# DDR16SS0_CTLPHY_WRAP_CTL_CFG_CTLCFG register map
Vendor: Texas Instruments
Registers are 32-bit, read-write, reset 0x0 unless marked. A register's access mark holds for its fields unless they carry their own. Offsets are as the file gives them; [hi:lo] are bit positions; {n}, {i} and the like mark numbered series.

## DDR16SS0_CTLPHY_WRAP_CTL_CFG_CTLCFG (part 6 of 9)
0x23DC CTLPHY_WRAP__CTL_CFG__CTLCFG_DENALI_PI_247
  [20:0] PI_TDFI_CTRLUPD_MAX_F0 — Defines the DFI tCTRLUPD_MAX timing parameter [in DFI clocks] for frequency set 0, the maximum cycles that dfi_ctrlupd_req can be asserted. If programmed to a non-zero, a timing violation will cause an interrupt and bit [1] set in the PI_UPDATE_ERROR_STATUS parameter.
0x23E0 CTLPHY_WRAP__CTL_CFG__CTLCFG_DENALI_PI_248
  [31:0] PI_TDFI_CTRLUPD_INTERVAL_F0 — Defines the DFI tCTRLUPD_INTERVAL timing parameter [in DFI clocks] for frequency set 0, the maximum cycles between dfi_ctrlupd_req assertions. If programmed to a non-zero, a timing violation will cause an interrupt and bit [0] set in the PI_UPDATE_ERROR_STATUS parameter.
0x23E4 CTLPHY_WRAP__CTL_CFG__CTLCFG_DENALI_PI_249
  [20:0] PI_TDFI_CTRLUPD_MAX_F1 — Defines the DFI tCTRLUPD_MAX timing parameter [in DFI clocks] for frequency set 1, the maximum cycles that dfi_ctrlupd_req can be asserted. If programmed to a non-zero, a timing violation will cause an interrupt and bit [1] set in the PI_UPDATE_ERROR_STATUS parameter.
0x23E8 CTLPHY_WRAP__CTL_CFG__CTLCFG_DENALI_PI_250
  [31:0] PI_TDFI_CTRLUPD_INTERVAL_F1 — Defines the DFI tCTRLUPD_INTERVAL timing parameter [in DFI clocks] for frequency set 1, the maximum cycles between dfi_ctrlupd_req assertions. If programmed to a non-zero, a timing violation will cause an interrupt and bit [0] set in the PI_UPDATE_ERROR_STATUS parameter.
0x23EC CTLPHY_WRAP__CTL_CFG__CTLCFG_DENALI_PI_251
  [20:0] PI_TDFI_CTRLUPD_MAX_F2 — Defines the DFI tCTRLUPD_MAX timing parameter [in DFI clocks] for frequency set 2, the maximum cycles that dfi_ctrlupd_req can be asserted. If programmed to a non-zero, a timing violation will cause an interrupt and bit [1] set in the PI_UPDATE_ERROR_STATUS parameter.
0x23F0 CTLPHY_WRAP__CTL_CFG__CTLCFG_DENALI_PI_252
  [31:0] PI_TDFI_CTRLUPD_INTERVAL_F2 — Defines the DFI tCTRLUPD_INTERVAL timing parameter [in DFI clocks] for frequency set 2, the maximum cycles between dfi_ctrlupd_req assertions. If programmed to a non-zero, a timing violation will cause an interrupt and bit [0] set in the PI_UPDATE_ERROR_STATUS parameter.
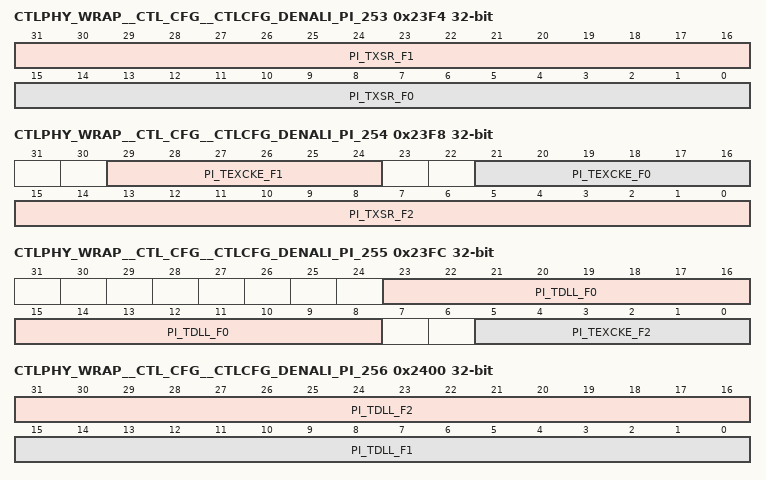
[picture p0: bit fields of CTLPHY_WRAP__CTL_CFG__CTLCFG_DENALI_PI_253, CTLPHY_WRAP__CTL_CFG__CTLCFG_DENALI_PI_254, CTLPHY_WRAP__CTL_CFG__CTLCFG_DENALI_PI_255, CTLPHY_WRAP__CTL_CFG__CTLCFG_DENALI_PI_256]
0x23F4 CTLPHY_WRAP__CTL_CFG__CTLCFG_DENALI_PI_253
  [31:16] PI_TXSR_F1 — DRAM TXSR value for frequency set 1 in cycles.
  [15:0] PI_TXSR_F0 — DRAM TXSR value for frequency set 0 in cycles.
0x23F8 CTLPHY_WRAP__CTL_CFG__CTLCFG_DENALI_PI_254
  [29:24] PI_TEXCKE_F1 — DRAM CKE low after SREF command timing for frequency set 1.
  [21:16] PI_TEXCKE_F0 — DRAM CKE low after SREF command timing for frequency set 0.
  [15:0] PI_TXSR_F2 — DRAM TXSR value for frequency set 2 in cycles.
0x23FC CTLPHY_WRAP__CTL_CFG__CTLCFG_DENALI_PI_255
  [23:8] PI_TDLL_F0 — DRAM tDLL value for frequency set 0 in cycles.
  [5:0] PI_TEXCKE_F2 — DRAM CKE low after SREF command timing for frequency set 2.
0x2400 CTLPHY_WRAP__CTL_CFG__CTLCFG_DENALI_PI_256
  [31:16] PI_TDLL_F2 — DRAM tDLL value for frequency set 2 in cycles.
  [15:0] PI_TDLL_F1 — DRAM tDLL value for frequency set 1 in cycles.
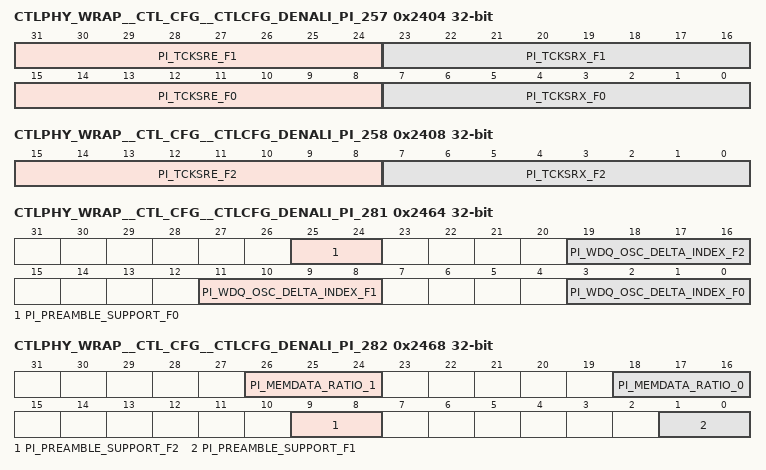
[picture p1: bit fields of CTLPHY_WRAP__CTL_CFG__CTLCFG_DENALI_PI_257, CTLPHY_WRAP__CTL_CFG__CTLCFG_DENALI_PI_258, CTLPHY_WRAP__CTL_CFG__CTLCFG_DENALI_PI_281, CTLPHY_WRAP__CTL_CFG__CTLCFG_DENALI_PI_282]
0x2404 CTLPHY_WRAP__CTL_CFG__CTLCFG_DENALI_PI_257
  [31:24] PI_TCKSRE_F1 — DRAM tCKSRE value.
  [23:16] PI_TCKSRX_F1 — DRAM tCKSRX value.
  [15:8] PI_TCKSRE_F0 — DRAM tCKSRE value.
  [7:0] PI_TCKSRX_F0 — DRAM tCKSRX value.
0x2408 CTLPHY_WRAP__CTL_CFG__CTLCFG_DENALI_PI_258
  [15:8] PI_TCKSRE_F2 — DRAM tCKSRE value.
  [7:0] PI_TCKSRX_F2 — DRAM tCKSRX value.
0x240C CTLPHY_WRAP__CTL_CFG__CTLCFG_DENALI_PI_259
  [23:0] PI_TINIT_F0 — DRAM tINIT value for frequency set 0 in cycles.
{0x2000+4i} CTLPHY_WRAP__CTL_CFG__CTLCFG_DENALI_PI_{i} (i=260..262)
  [23:0] PI_TINIT{i-257}_F0 — DRAM tINIT{i-257} value for frequency set 0 in cycles.
0x241C CTLPHY_WRAP__CTL_CFG__CTLCFG_DENALI_PI_263
  [15:0] PI_TXSNR_F0 — DRAM tXSNR value for frequency set 0 in cycles.
0x2420 CTLPHY_WRAP__CTL_CFG__CTLCFG_DENALI_PI_264
  [23:0] PI_TINIT_F1 — DRAM tINIT value for frequency set 1 in cycles.
{0x2000+4i} CTLPHY_WRAP__CTL_CFG__CTLCFG_DENALI_PI_{i} (i=265..267)
  [23:0] PI_TINIT{i-262}_F1 — DRAM tINIT{i-262} value for frequency set 1 in cycles.
0x2430 CTLPHY_WRAP__CTL_CFG__CTLCFG_DENALI_PI_268
  [15:0] PI_TXSNR_F1 — DRAM tXSNR value for frequency set 1 in cycles.
0x2434 CTLPHY_WRAP__CTL_CFG__CTLCFG_DENALI_PI_269
  [23:0] PI_TINIT_F2 — DRAM tINIT value for frequency set 2 in cycles.
{0x2000+4i} CTLPHY_WRAP__CTL_CFG__CTLCFG_DENALI_PI_{i} (i=270..272)
  [23:0] PI_TINIT{i-267}_F2 — DRAM tINIT{i-267} value for frequency set 2 in cycles.
0x2444 CTLPHY_WRAP__CTL_CFG__CTLCFG_DENALI_PI_273
  [15:0] PI_TXSNR_F2 — DRAM tXSNR value for frequency set 2 in cycles.
0x2448 CTLPHY_WRAP__CTL_CFG__CTLCFG_DENALI_PI_274
  [27:16] PI_TZQCAL_F0 — Holds the DRAM ZQCAL value for frequency set 0 in cycles.
0x244C CTLPHY_WRAP__CTL_CFG__CTLCFG_DENALI_PI_275
  [6:0] PI_TZQLAT_F0 — Holds the DRAM ZQLAT value for frequency set 0 in cycles.
0x2450 CTLPHY_WRAP__CTL_CFG__CTLCFG_DENALI_PI_276
  [27:16] PI_TZQCAL_F1 — Holds the DRAM ZQCAL value for frequency set 1 in cycles.
0x2454 CTLPHY_WRAP__CTL_CFG__CTLCFG_DENALI_PI_277
  [6:0] PI_TZQLAT_F1 — Holds the DRAM ZQLAT value for frequency set 1 in cycles.
0x2458 CTLPHY_WRAP__CTL_CFG__CTLCFG_DENALI_PI_278
  [27:16] PI_TZQCAL_F2 — Holds the DRAM ZQCAL value for frequency set 2 in cycles.
0x245C CTLPHY_WRAP__CTL_CFG__CTLCFG_DENALI_PI_279
  [6:0] PI_TZQLAT_F2 — Holds the DRAM ZQLAT value for frequency set 2 in cycles.
0x2460 CTLPHY_WRAP__CTL_CFG__CTLCFG_DENALI_PI_280 access not given reset not defined
0x2464 CTLPHY_WRAP__CTL_CFG__CTLCFG_DENALI_PI_281
  [25:24] PI_PREAMBLE_SUPPORT_F0 — bit0: Selection of one or two cycle preamble for read burst transfers. bit1: Selection of one or two cycles write burst transfers for NON-DDR5,one or multi[up to four] cycles write burst transfers for DDR5.
  [19:16] PI_WDQ_OSC_DELTA_INDEX_F2 — WDQ DQS delay delta index for OSC triggered periodic training for frequency set 2. If the value is n, the delay is 2^n/512 cycle.
  [11:8] PI_WDQ_OSC_DELTA_INDEX_F1 — WDQ DQS delay delta index for OSC triggered periodic training for frequency set 1. If the value is n, the delay is 2^n/512 cycle.
  [3:0] PI_WDQ_OSC_DELTA_INDEX_F0 — WDQ DQS delay delta index for OSC triggered periodic training for frequency set 0. If the value is n, the delay is 2^n/512 cycle.
0x2468 CTLPHY_WRAP__CTL_CFG__CTLCFG_DENALI_PI_282
  [26:24] PI_MEMDATA_RATIO_1 — Defines the ratio of the DRAM device size on chip select 1 to the memory data width. Program with the log2 ratio of the memory data width to the device data width.
  [18:16] PI_MEMDATA_RATIO_0 — Defines the ratio of the DRAM device size on chip select 0 to the memory data width. Program with the log2 ratio of the memory data width to the device data width.
  [9:8] PI_PREAMBLE_SUPPORT_F2 — bit0: Selection of one or two cycle preamble for read burst transfers. bit1: Selection of one or two cycles write burst transfers for NON-DDR5,one or multi[up to four] cycles write burst transfers for DDR5.
  [1:0] PI_PREAMBLE_SUPPORT_F1 — bit0: Selection of one or two cycle preamble for read burst transfers. bit1: Selection of one or two cycles write burst transfers for NON-DDR5,one or multi[up to four] cycles write burst transfers for DDR5.
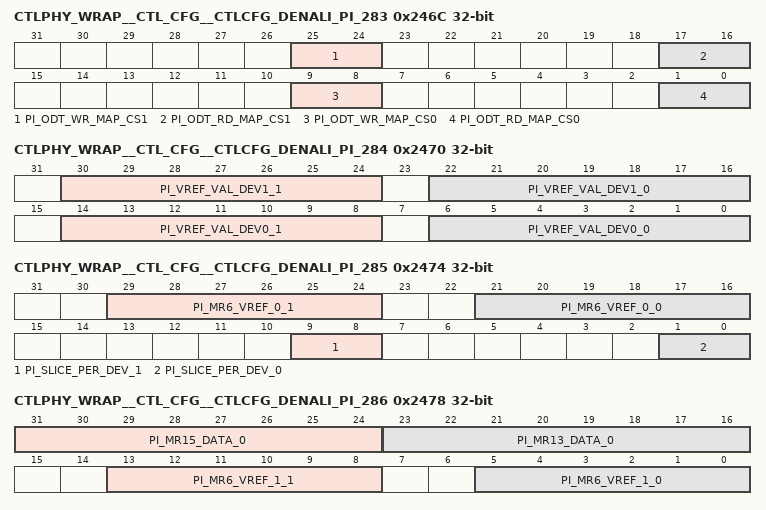
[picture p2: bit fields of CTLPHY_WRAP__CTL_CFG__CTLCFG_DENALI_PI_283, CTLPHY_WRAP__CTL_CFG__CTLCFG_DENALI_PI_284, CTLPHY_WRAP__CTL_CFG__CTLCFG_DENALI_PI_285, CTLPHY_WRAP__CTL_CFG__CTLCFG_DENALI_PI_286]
0x246C CTLPHY_WRAP__CTL_CFG__CTLCFG_DENALI_PI_283
  [25:24] PI_ODT_WR_MAP_CS1 — Determines which chip[s] will have termination when a write occurs on chip select 1. Set bit X to enable termination on csX when cs1 is performing a write.
  [17:16] PI_ODT_RD_MAP_CS1 — Determines which chip[s] will have termination when a read occurs on chip select 1. Set bit X to enable termination on csX when cs1 is performing a read.
  [9:8] PI_ODT_WR_MAP_CS0 — Determines which chip[s] will have termination when a write occurs on chip select 0. Set bit X to enable termination on csX when cs0 is performing a write.
  [1:0] PI_ODT_RD_MAP_CS0 — Determines which chip[s] will have termination when a read occurs on chip select 0. Set bit X to enable termination on csX when cs0 is performing a read.
0x2470 CTLPHY_WRAP__CTL_CFG__CTLCFG_DENALI_PI_284
  [30:24] PI_VREF_VAL_DEV1_1 — Defines the range and value for VREF training for DRAM 1 for CS 1. If the PI_VREF_PDA_EN parameter is not set, device 0 values are used for all devices.
  [22:16] PI_VREF_VAL_DEV1_0 — Defines the range and value for VREF training for DRAM 1 for CS 0. If the PI_VREF_PDA_EN parameter is not set, device 0 values are used for all devices.
  [14:8] PI_VREF_VAL_DEV0_1 — Defines the range and value for VREF training for DRAM 0 for CS 1. If the PI_VREF_PDA_EN parameter is not set, device 0 values are used for all devices.
  [6:0] PI_VREF_VAL_DEV0_0 — Defines the range and value for VREF training for DRAM 0 for CS 0. If the PI_VREF_PDA_EN parameter is not set, device 0 values are used for all devices.
0x2474 CTLPHY_WRAP__CTL_CFG__CTLCFG_DENALI_PI_285 access per field
  [29:24] PI_MR6_VREF_0_1 ro — The parameter stores the vref value of every devices of the same CS. It is updated after WDQLVL PDA mode completed. READ-ONLY.
  [21:16] PI_MR6_VREF_0_0 ro — The parameter stores the vref value of every devices of the same CS. It is updated after WDQLVL PDA mode completed. READ-ONLY.
  [9:8] PI_SLICE_PER_DEV_1 rw — Indicates the number of data slices per memory device. The device width divided by 8.
  [1:0] PI_SLICE_PER_DEV_0 rw — Indicates the number of data slices per memory device. The device width divided by 8.
0x2478 CTLPHY_WRAP__CTL_CFG__CTLCFG_DENALI_PI_286 access per field
  [31:24] PI_MR15_DATA_0 rw — Data to program into memory mode register 15 for chip select 0.
  [23:16] PI_MR13_DATA_0 rw — Data to program into memory mode register 13 for chip select 0.
  [13:8] PI_MR6_VREF_1_1 ro — The parameter stores the vref value of every devices of the same CS. It is updated after WDQLVL PDA mode completed. READ-ONLY.
  [5:0] PI_MR6_VREF_1_0 ro — The parameter stores the vref value of every devices of the same CS. It is updated after WDQLVL PDA mode completed. READ-ONLY.
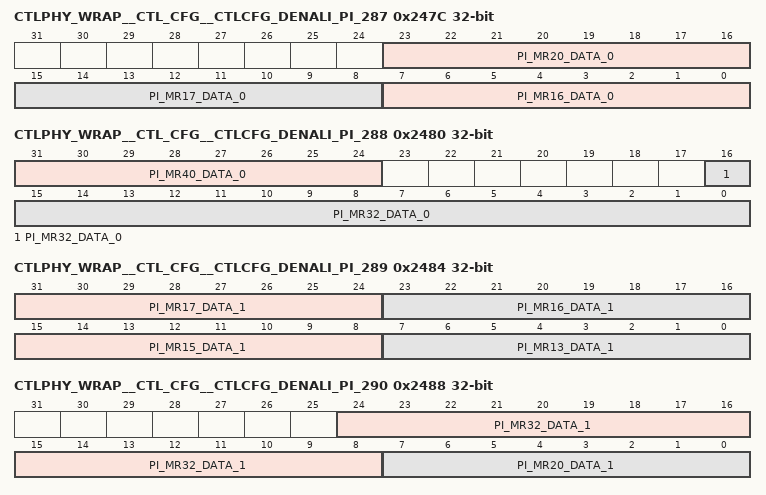
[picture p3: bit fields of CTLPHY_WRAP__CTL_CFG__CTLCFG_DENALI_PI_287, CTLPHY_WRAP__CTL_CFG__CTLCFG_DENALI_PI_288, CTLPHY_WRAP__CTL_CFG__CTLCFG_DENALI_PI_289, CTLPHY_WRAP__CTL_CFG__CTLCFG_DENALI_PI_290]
0x247C CTLPHY_WRAP__CTL_CFG__CTLCFG_DENALI_PI_287
  [23:16] PI_MR20_DATA_0 — Data to program into memory mode register 20 for chip select 0.
  [15:8] PI_MR17_DATA_0 — Data to program into memory mode register 17 for chip select 0.
  [7:0] PI_MR16_DATA_0 — Data to program into memory mode register 16 for chip select 0.
0x2480 CTLPHY_WRAP__CTL_CFG__CTLCFG_DENALI_PI_288
  [31:24] PI_MR40_DATA_0 — Data to program into memory mode register 40 for chip select 0.
  [16:0] PI_MR32_DATA_0 — Data to program into memory mode register 32 for chip select 0.
0x2484 CTLPHY_WRAP__CTL_CFG__CTLCFG_DENALI_PI_289
  [31:24] PI_MR17_DATA_1 — Data to program into memory mode register 17 for chip select 1.
  [23:16] PI_MR16_DATA_1 — Data to program into memory mode register 16 for chip select 1.
  [15:8] PI_MR15_DATA_1 — Data to program into memory mode register 15 for chip select 1.
  [7:0] PI_MR13_DATA_1 — Data to program into memory mode register 13 for chip select 1.
0x2488 CTLPHY_WRAP__CTL_CFG__CTLCFG_DENALI_PI_290
  [24:8] PI_MR32_DATA_1 — Data to program into memory mode register 32 for chip select 1.
  [7:0] PI_MR20_DATA_1 — Data to program into memory mode register 20 for chip select 1.
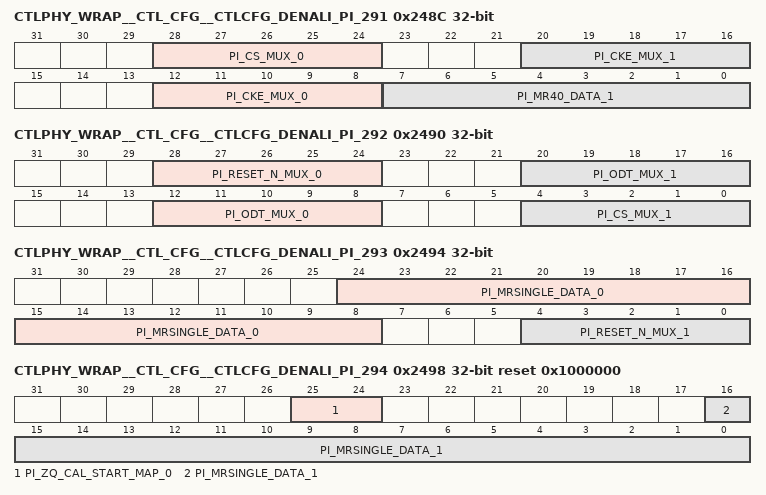
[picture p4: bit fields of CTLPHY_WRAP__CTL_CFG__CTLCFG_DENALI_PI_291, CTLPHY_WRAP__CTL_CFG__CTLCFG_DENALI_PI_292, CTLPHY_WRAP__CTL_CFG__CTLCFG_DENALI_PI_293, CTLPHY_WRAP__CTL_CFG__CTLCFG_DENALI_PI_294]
0x248C CTLPHY_WRAP__CTL_CFG__CTLCFG_DENALI_PI_291
  [28:24] PI_CS_MUX_0 — Command pin CS_0 mux selector
  [20:16] PI_CKE_MUX_1 — Command pin CKE_1 mux selector
  [12:8] PI_CKE_MUX_0 — Command pin CKE_0 mux selector
  [7:0] PI_MR40_DATA_1 — Data to program into memory mode register 40 for chip select 1.
0x2490 CTLPHY_WRAP__CTL_CFG__CTLCFG_DENALI_PI_292
  [28:24] PI_RESET_N_MUX_0 — Command pin RESET_N_0 mux selector
  [20:16] PI_ODT_MUX_1 — Command pin ODT_1 mux selector
  [12:8] PI_ODT_MUX_0 — Command pin ODT_0 mux selector
  [4:0] PI_CS_MUX_1 — Command pin CS_1 mux selector
0x2494 CTLPHY_WRAP__CTL_CFG__CTLCFG_DENALI_PI_293
  [24:8] PI_MRSINGLE_DATA_0 — Data to program into memory mode register single write to chip select 0.
  [4:0] PI_RESET_N_MUX_1 — Command pin RESET_N_1 mux selector
0x2498 CTLPHY_WRAP__CTL_CFG__CTLCFG_DENALI_PI_294 reset 0x1000000
  [25:24] PI_ZQ_CAL_START_MAP_0 — Defines which chip select[s] will receive ZQ calibration start commands simultaneously on iteration 0 of the ZQ START initialization and periodic command sequences. Clear to all zeros for no ZQ START commands.
  [16:0] PI_MRSINGLE_DATA_1 — Data to program into memory mode register single write to chip select 1.
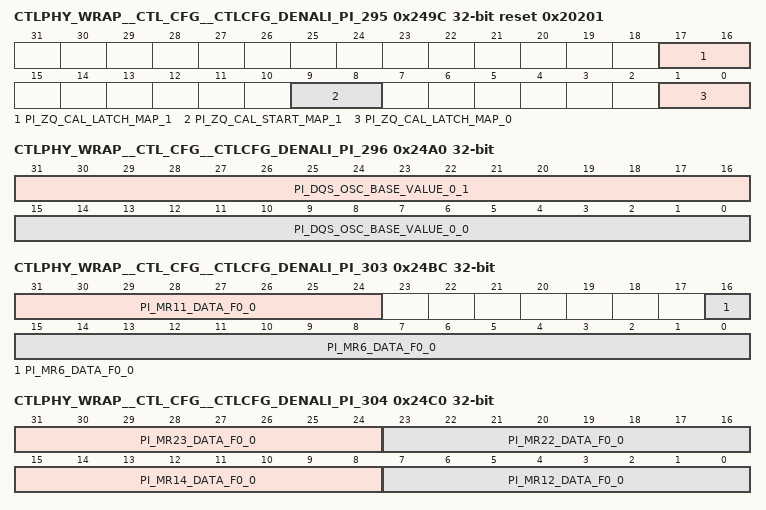
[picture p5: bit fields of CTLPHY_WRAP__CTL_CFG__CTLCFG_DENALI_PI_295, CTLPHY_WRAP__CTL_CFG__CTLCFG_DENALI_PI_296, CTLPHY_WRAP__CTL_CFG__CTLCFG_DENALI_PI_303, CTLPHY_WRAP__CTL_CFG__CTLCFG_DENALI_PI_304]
0x249C CTLPHY_WRAP__CTL_CFG__CTLCFG_DENALI_PI_295 reset 0x20201
  [17:16] PI_ZQ_CAL_LATCH_MAP_1 — Defines which chip select[s] will receive ZQ calibration latch commands simultaneously on iteration 1 of the ZQ LATCH initialization and periodic command sequences. Clear to all zeros for no ZQ LATCH commands.
  [9:8] PI_ZQ_CAL_START_MAP_1 — Defines which chip select[s] will receive ZQ calibration start commands simultaneously on iteration 1 of the ZQ START initialization and periodic command sequences. Clear to all zeros for no ZQ START commands.
  [1:0] PI_ZQ_CAL_LATCH_MAP_0 — Defines which chip select[s] will receive ZQ calibration latch commands simultaneously on iteration 0 of the ZQ LATCH initialization and periodic command sequences. Clear to all zeros for no ZQ LATCH commands.
0x24A0 CTLPHY_WRAP__CTL_CFG__CTLCFG_DENALI_PI_296
  [31:16] PI_DQS_OSC_BASE_VALUE_0_1 — Base value for comparison of oscillator measurement for device 0 of rank 1
  [15:0] PI_DQS_OSC_BASE_VALUE_0_0 — Base value for comparison of oscillator measurement for device 0 of rank 0
{0x2000+4i} CTLPHY_WRAP__CTL_CFG__CTLCFG_DENALI_PI_{i} (i=297..302)
  [16:0] PI_MR{i-297}_DATA_F0_0 — Data to program into memory mode register {i-297} for chip select 0 for frequency set 0.
0x24BC CTLPHY_WRAP__CTL_CFG__CTLCFG_DENALI_PI_303
  [31:24] PI_MR11_DATA_F0_0 — Data to program into memory mode register 11 for chip select 0 for frequency set 0.
  [16:0] PI_MR6_DATA_F0_0 — Data to program into memory mode register 6 for chip select 0 for frequency set 0.
0x24C0 CTLPHY_WRAP__CTL_CFG__CTLCFG_DENALI_PI_304
  [31:24] PI_MR23_DATA_F0_0 — Data to program into memory mode register 23 for chip select 0 for frequency set 0.
  [23:16] PI_MR22_DATA_F0_0 — Data to program into memory mode register 22 for chip select 0 for frequency set 0.
  [15:8] PI_MR14_DATA_F0_0 — Data to program into memory mode register 14 for chip select 0 for frequency set 0.
  [7:0] PI_MR12_DATA_F0_0 — Data to program into memory mode register 12 for chip select 0 for frequency set 0.
{0x2000+4i} CTLPHY_WRAP__CTL_CFG__CTLCFG_DENALI_PI_{i} (i=305..310)
  [16:0] PI_MR{i-305}_DATA_F1_0 — Data to program into memory mode register {i-305} for chip select 0 for frequency set 1.
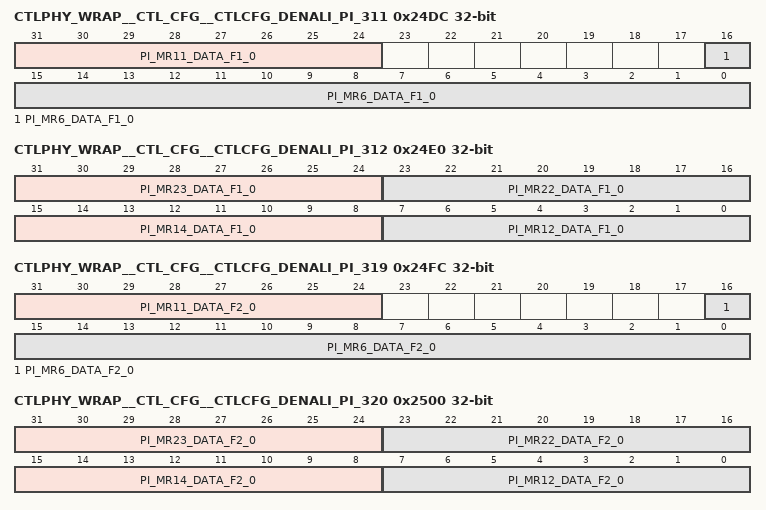
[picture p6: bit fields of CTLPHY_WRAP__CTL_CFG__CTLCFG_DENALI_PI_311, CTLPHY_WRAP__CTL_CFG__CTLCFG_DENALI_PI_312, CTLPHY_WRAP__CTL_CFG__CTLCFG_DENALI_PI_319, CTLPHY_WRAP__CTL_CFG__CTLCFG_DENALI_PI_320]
0x24DC CTLPHY_WRAP__CTL_CFG__CTLCFG_DENALI_PI_311
  [31:24] PI_MR11_DATA_F1_0 — Data to program into memory mode register 11 for chip select 0 for frequency set 1.
  [16:0] PI_MR6_DATA_F1_0 — Data to program into memory mode register 6 for chip select 0 for frequency set 1.
0x24E0 CTLPHY_WRAP__CTL_CFG__CTLCFG_DENALI_PI_312
  [31:24] PI_MR23_DATA_F1_0 — Data to program into memory mode register 23 for chip select 0 for frequency set 1.
  [23:16] PI_MR22_DATA_F1_0 — Data to program into memory mode register 22 for chip select 0 for frequency set 1.
  [15:8] PI_MR14_DATA_F1_0 — Data to program into memory mode register 14 for chip select 0 for frequency set 1.
  [7:0] PI_MR12_DATA_F1_0 — Data to program into memory mode register 12 for chip select 0 for frequency set 1.
{0x2000+4i} CTLPHY_WRAP__CTL_CFG__CTLCFG_DENALI_PI_{i} (i=313..318)
  [16:0] PI_MR{i-313}_DATA_F2_0 — Data to program into memory mode register {i-313} for chip select 0 for frequency set 2.
0x24FC CTLPHY_WRAP__CTL_CFG__CTLCFG_DENALI_PI_319
  [31:24] PI_MR11_DATA_F2_0 — Data to program into memory mode register 11 for chip select 0 for frequency set 2.
  [16:0] PI_MR6_DATA_F2_0 — Data to program into memory mode register 6 for chip select 0 for frequency set 2.
0x2500 CTLPHY_WRAP__CTL_CFG__CTLCFG_DENALI_PI_320
  [31:24] PI_MR23_DATA_F2_0 — Data to program into memory mode register 23 for chip select 0 for frequency set 2.
  [23:16] PI_MR22_DATA_F2_0 — Data to program into memory mode register 22 for chip select 0 for frequency set 2.
  [15:8] PI_MR14_DATA_F2_0 — Data to program into memory mode register 14 for chip select 0 for frequency set 2.
  [7:0] PI_MR12_DATA_F2_0 — Data to program into memory mode register 12 for chip select 0 for frequency set 2.
{0x2000+4i} CTLPHY_WRAP__CTL_CFG__CTLCFG_DENALI_PI_{i} (i=321..326)
  [16:0] PI_MR{i-321}_DATA_F0_1 — Data to program into memory mode register {i-321} for chip select 1 for frequency set 0.
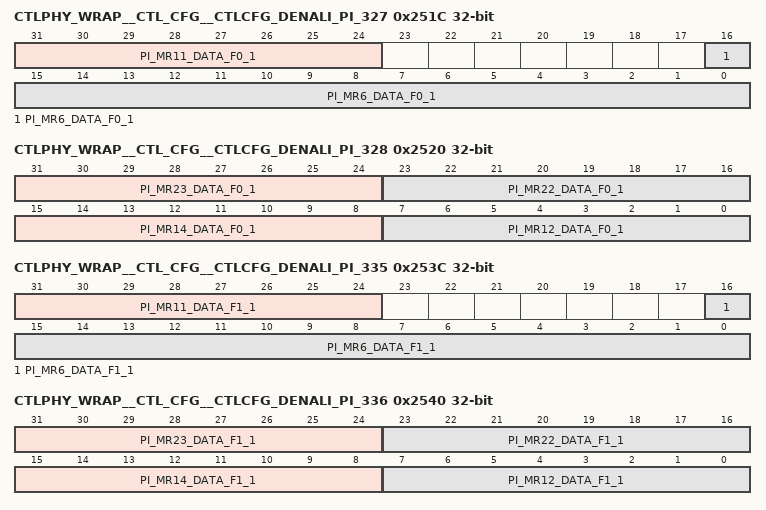
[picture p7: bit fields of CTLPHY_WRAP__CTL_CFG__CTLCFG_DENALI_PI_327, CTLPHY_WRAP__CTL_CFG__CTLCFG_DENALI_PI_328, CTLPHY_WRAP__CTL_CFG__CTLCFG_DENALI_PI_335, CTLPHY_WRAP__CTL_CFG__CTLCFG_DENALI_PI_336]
0x251C CTLPHY_WRAP__CTL_CFG__CTLCFG_DENALI_PI_327
  [31:24] PI_MR11_DATA_F0_1 — Data to program into memory mode register 11 for chip select 1 for frequency set 0.
  [16:0] PI_MR6_DATA_F0_1 — Data to program into memory mode register 6 for chip select 1 for frequency set 0.
0x2520 CTLPHY_WRAP__CTL_CFG__CTLCFG_DENALI_PI_328
  [31:24] PI_MR23_DATA_F0_1 — Data to program into memory mode register 23 for chip select 1 for frequency set 0.
  [23:16] PI_MR22_DATA_F0_1 — Data to program into memory mode register 22 for chip select 1 for frequency set 0.
  [15:8] PI_MR14_DATA_F0_1 — Data to program into memory mode register 14 for chip select 1 for frequency set 0.
  [7:0] PI_MR12_DATA_F0_1 — Data to program into memory mode register 12 for chip select 1 for frequency set 0.
{0x2000+4i} CTLPHY_WRAP__CTL_CFG__CTLCFG_DENALI_PI_{i} (i=329..334)
  [16:0] PI_MR{i-329}_DATA_F1_1 — Data to program into memory mode register {i-329} for chip select 1 for frequency set 1.
0x253C CTLPHY_WRAP__CTL_CFG__CTLCFG_DENALI_PI_335
  [31:24] PI_MR11_DATA_F1_1 — Data to program into memory mode register 11 for chip select 1 for frequency set 1.
  [16:0] PI_MR6_DATA_F1_1 — Data to program into memory mode register 6 for chip select 1 for frequency set 1.
0x2540 CTLPHY_WRAP__CTL_CFG__CTLCFG_DENALI_PI_336
  [31:24] PI_MR23_DATA_F1_1 — Data to program into memory mode register 23 for chip select 1 for frequency set 1.
  [23:16] PI_MR22_DATA_F1_1 — Data to program into memory mode register 22 for chip select 1 for frequency set 1.
  [15:8] PI_MR14_DATA_F1_1 — Data to program into memory mode register 14 for chip select 1 for frequency set 1.
  [7:0] PI_MR12_DATA_F1_1 — Data to program into memory mode register 12 for chip select 1 for frequency set 1.
{0x2000+4i} CTLPHY_WRAP__CTL_CFG__CTLCFG_DENALI_PI_{i} (i=337..342)
  [16:0] PI_MR{i-337}_DATA_F2_1 — Data to program into memory mode register {i-337} for chip select 1 for frequency set 2.
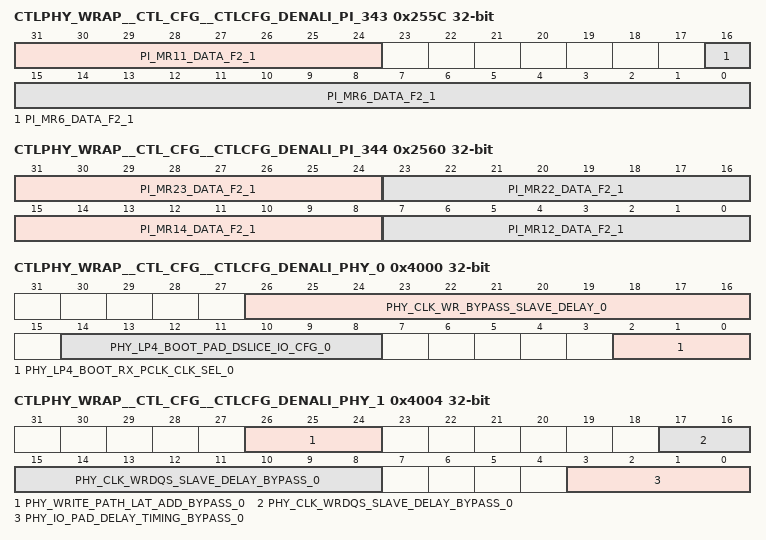
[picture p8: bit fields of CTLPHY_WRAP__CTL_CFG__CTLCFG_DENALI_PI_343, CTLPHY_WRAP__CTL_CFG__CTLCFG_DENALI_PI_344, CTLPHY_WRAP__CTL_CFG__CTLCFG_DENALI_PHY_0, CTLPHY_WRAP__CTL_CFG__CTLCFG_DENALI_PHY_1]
0x255C CTLPHY_WRAP__CTL_CFG__CTLCFG_DENALI_PI_343
  [31:24] PI_MR11_DATA_F2_1 — Data to program into memory mode register 11 for chip select 1 for frequency set 2.
  [16:0] PI_MR6_DATA_F2_1 — Data to program into memory mode register 6 for chip select 1 for frequency set 2.
0x2560 CTLPHY_WRAP__CTL_CFG__CTLCFG_DENALI_PI_344
  [31:24] PI_MR23_DATA_F2_1 — Data to program into memory mode register 23 for chip select 1 for frequency set 2.
  [23:16] PI_MR22_DATA_F2_1 — Data to program into memory mode register 22 for chip select 1 for frequency set 2.
  [15:8] PI_MR14_DATA_F2_1 — Data to program into memory mode register 14 for chip select 1 for frequency set 2.
  [7:0] PI_MR12_DATA_F2_1 — Data to program into memory mode register 12 for chip select 1 for frequency set 2.
0x4000 CTLPHY_WRAP__CTL_CFG__CTLCFG_DENALI_PHY_0
  [26:16] PHY_CLK_WR_BYPASS_SLAVE_DELAY_0 — Write data clock bypass mode slave delay setting for slice 0.
  [14:8] PHY_LP4_BOOT_PAD_DSLICE_IO_CFG_0 — Controls PCLK/PARK pin for pad for slice 0 with boot frequency.
  [2:0] PHY_LP4_BOOT_RX_PCLK_CLK_SEL_0 — RX_PCLK boot clock frequency selection for slice 0.
0x4004 CTLPHY_WRAP__CTL_CFG__CTLCFG_DENALI_PHY_1
  [26:24] PHY_WRITE_PATH_LAT_ADD_BYPASS_0 — Number of cycles on bypass mode to delay the incoming dfi_wrdata_en/dfi_wrdata signals for slice 0.
  [17:8] PHY_CLK_WRDQS_SLAVE_DELAY_BYPASS_0 — Write DQS bypass mode slave delay setting for slice 0.
  [3:0] PHY_IO_PAD_DELAY_TIMING_BYPASS_0 — Feedback pad's OPAD and IPAD delay timing on bypass mode for slice 0.
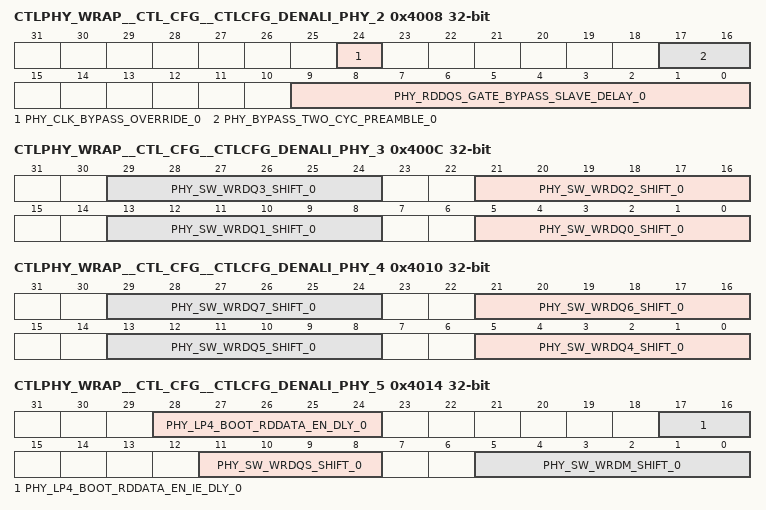
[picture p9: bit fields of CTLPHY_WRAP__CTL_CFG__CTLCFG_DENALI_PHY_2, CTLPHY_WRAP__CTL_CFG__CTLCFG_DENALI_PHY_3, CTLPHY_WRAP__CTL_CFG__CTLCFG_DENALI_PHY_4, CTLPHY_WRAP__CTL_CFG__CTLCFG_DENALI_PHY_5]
0x4008 CTLPHY_WRAP__CTL_CFG__CTLCFG_DENALI_PHY_2
  [24] PHY_CLK_BYPASS_OVERRIDE_0 — Bypass mode override setting for slice 0.
  [17:16] PHY_BYPASS_TWO_CYC_PREAMBLE_0 — Two_cycle_preamble for bypass mode for slice 0.
  [9:0] PHY_RDDQS_GATE_BYPASS_SLAVE_DELAY_0 — Read DQS bypass mode slave delay setting for slice 0.
0x400C CTLPHY_WRAP__CTL_CFG__CTLCFG_DENALI_PHY_3
  [8n+5:8n] PHY_SW_WRDQ{n}_SHIFT_0 (n=0..3) — Manual override of automatic half_cycle_shift/cycle_shift for write DQ{n} for slice 0. Bit [0] enables override of half_cycle_shift. Bit [1] is the half_cycle_shift value. Bit [2] enables override of cycle shift. Bits [4:3] are the cycle_shift value.
0x4010 CTLPHY_WRAP__CTL_CFG__CTLCFG_DENALI_PHY_4
  [8n-27:8n-32] PHY_SW_WRDQ{n}_SHIFT_0 (n=4..7) — Manual override of automatic half_cycle_shift/cycle_shift for write DQ{n} for slice 0. Bit [0] enables override of half_cycle_shift. Bit [1] is the half_cycle_shift value. Bit [2] enables override of cycle shift. Bits [4:3] are the cycle_shift value.
0x4014 CTLPHY_WRAP__CTL_CFG__CTLCFG_DENALI_PHY_5
  [28:24] PHY_LP4_BOOT_RDDATA_EN_DLY_0 — For LPDDR4 boot frequency, the number of cycles that the dfi_rddata_en signal is early for slice 0.
  [17:16] PHY_LP4_BOOT_RDDATA_EN_IE_DLY_0 — For LPDDR4 boot frequency, the number of cycles that the dfi_rddata_en signal is earlier than necessary for input enable generation for slice 0.
  [11:8] PHY_SW_WRDQS_SHIFT_0 — Manual override of automatic half_cycle_shift/cycle_shift for write DQS for slice 0. Bit [0] enables override of half_cycle_shift. Bit [1] is the half_cycle_shift value. Bit [2] enables override of cycle shift. Bit [3] is the cycle_shift value.
  [5:0] PHY_SW_WRDM_SHIFT_0 — Manual override of automatic half_cycle_shift/cycle_shift for write DM for slice 0. Bit [0] enables override of half_cycle_shift. Bit [1] is the half_cycle_shift value. Bit [2] enables override of cycle shift. Bits [4:3] are the cycle_shift value.
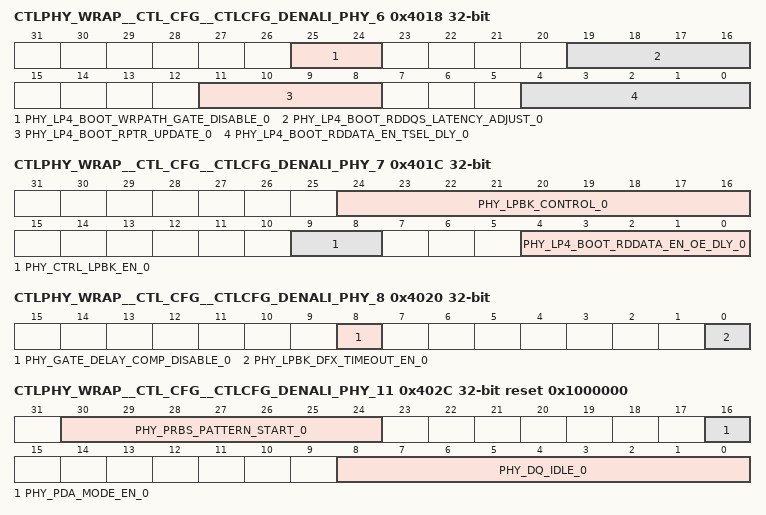
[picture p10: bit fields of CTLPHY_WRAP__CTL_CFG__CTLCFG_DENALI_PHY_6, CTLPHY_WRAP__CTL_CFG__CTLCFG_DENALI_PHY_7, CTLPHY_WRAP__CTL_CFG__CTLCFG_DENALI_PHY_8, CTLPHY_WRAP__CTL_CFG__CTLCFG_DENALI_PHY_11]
0x4018 CTLPHY_WRAP__CTL_CFG__CTLCFG_DENALI_PHY_6
  [25:24] PHY_LP4_BOOT_WRPATH_GATE_DISABLE_0 — For LPDDR4 boot frequency, write path clock gating disable for slice 0. Bit [0]: disable pull in wrdata_en; Bit [1]: disable write path clock gating, clock always on
  [19:16] PHY_LP4_BOOT_RDDQS_LATENCY_ADJUST_0 — For LPDDR4 boot frequency, the number of cycles to delay the incoming dfi_rddata_en for read DQS gate generation for slice 0.
  [11:8] PHY_LP4_BOOT_RPTR_UPDATE_0 — For LPDDR4 boot frequency, the offset in cycles from the dfi_rddata_en signal to releasing data from the entry FIFO for slice 0.
  [4:0] PHY_LP4_BOOT_RDDATA_EN_TSEL_DLY_0 — For LPDDR4 boot frequency, the number of cycles that the dfi_rddata_en signal is earlier than necessary for TSEL enable generation for slice 0.
0x401C CTLPHY_WRAP__CTL_CFG__CTLCFG_DENALI_PHY_7
  [24:16] PHY_LPBK_CONTROL_0 — Loopback control bits for slice 0.
  [9:8] PHY_CTRL_LPBK_EN_0 — Loopback control en for slice 0.
  [4:0] PHY_LP4_BOOT_RDDATA_EN_OE_DLY_0 — For LPDDR4 boot frequency, the number of cycles that the dfi_rddata_en signal is earlier than necessary for extended OE generation for slice 0.
0x4020 CTLPHY_WRAP__CTL_CFG__CTLCFG_DENALI_PHY_8
  [8] PHY_GATE_DELAY_COMP_DISABLE_0 — use the control whether to compensate half_cycle when gate_slave_delay is larger than half_cycle for the gate close for slice 0.
  [0] PHY_LPBK_DFX_TIMEOUT_EN_0 — Loopback read only test timeout mechanism enable for slice 0.
0x4024 CTLPHY_WRAP__CTL_CFG__CTLCFG_DENALI_PHY_9
  [31:0] PHY_AUTO_TIMING_MARGIN_CONTROL_0 — Auto timing marging control bits for slice 0.
0x4028 CTLPHY_WRAP__CTL_CFG__CTLCFG_DENALI_PHY_10 ro
  [27:0] PHY_AUTO_TIMING_MARGIN_OBS_0 — Observation register for the auto_timing_margin for slice 0. READ-ONLY
0x402C CTLPHY_WRAP__CTL_CFG__CTLCFG_DENALI_PHY_11 reset 0x1000000
  [30:24] PHY_PRBS_PATTERN_START_0 — PRBS7 start pattern for slice 0.
  [16] PHY_PDA_MODE_EN_0 — When set to 1, the invalid DQs will be driven by the dfi_wrdata to make sure the tpda_s and tpda_h's timing is meet for slice 0.
  [8:0] PHY_DQ_IDLE_0 — When set to 1, the inavlid DQ will be driven to high, when set to 0, the invalid DQ will be driven to low for slice 0.
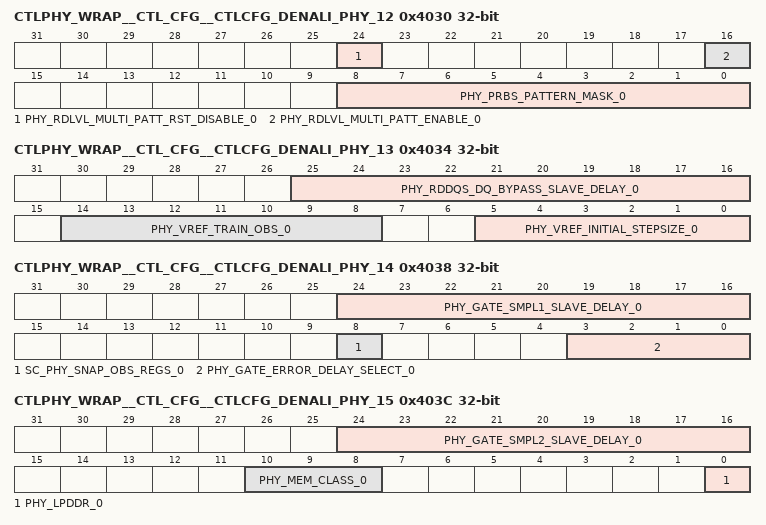
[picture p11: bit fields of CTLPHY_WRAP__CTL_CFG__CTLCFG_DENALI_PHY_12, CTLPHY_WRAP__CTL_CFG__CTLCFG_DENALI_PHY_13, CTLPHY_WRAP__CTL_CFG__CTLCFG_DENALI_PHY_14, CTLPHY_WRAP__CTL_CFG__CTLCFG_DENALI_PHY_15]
0x4030 CTLPHY_WRAP__CTL_CFG__CTLCFG_DENALI_PHY_12
  [24] PHY_RDLVL_MULTI_PATT_RST_DISABLE_0 — Read Leveling read level windows disable reset for slice 0.
  [16] PHY_RDLVL_MULTI_PATT_ENABLE_0 — Read Leveling Multi-pattern enable for slice 0.
  [8:0] PHY_PRBS_PATTERN_MASK_0 — PRBS7 mask signal for slice 0.
0x4034 CTLPHY_WRAP__CTL_CFG__CTLCFG_DENALI_PHY_13 access per field
  [25:16] PHY_RDDQS_DQ_BYPASS_SLAVE_DELAY_0 rw — Read DQS data clock bypass mode slave delay setting for slice 0.
  [14:8] PHY_VREF_TRAIN_OBS_0 ro — Observation register for best vref value for slice 0. READ-ONLY
  [5:0] PHY_VREF_INITIAL_STEPSIZE_0 rw — Data slice initial VREF training step size for slice 0.
0x4038 CTLPHY_WRAP__CTL_CFG__CTLCFG_DENALI_PHY_14 access per field
  [24:16] PHY_GATE_SMPL1_SLAVE_DELAY_0 rw — Number of cycles to delay the read DQS gate signal to generate gate1 signal for on-the-fly read DQS training for slice 0.
  [8] SC_PHY_SNAP_OBS_REGS_0 wo — Initiates a snapshot of the internal observation registers for slice 0. Set to 1 to trigger. WRITE-ONLY
  [3:0] PHY_GATE_ERROR_DELAY_SELECT_0 rw — Number of cycles to wait for the DQS gate to close before flagging an error for slice 0.
0x403C CTLPHY_WRAP__CTL_CFG__CTLCFG_DENALI_PHY_15
  [24:16] PHY_GATE_SMPL2_SLAVE_DELAY_0 — Number of cycles to delay the read DQS gate signal to generate gate2 signal for on-the-fly read DQS training for slice 0.
  [10:8] PHY_MEM_CLASS_0 — Indicates the type of DRAM for slice 0. 0 for DDR3, 1 for DDR4, 2 for DDR5, 4 for LPDDR2, 5 for LPDDR3. 6 for LPDDR4
  [0] PHY_LPDDR_0 — Adds a cycle of delay for the slice 0 to match the address slice. Set to 1 to add a cycle
0x4040 CTLPHY_WRAP__CTL_CFG__CTLCFG_DENALI_PHY_16
  [1:0] ON_FLY_GATE_ADJUST_EN_0 — Control the on-the-fly gate adjustment for slice 0.
0x4044 CTLPHY_WRAP__CTL_CFG__CTLCFG_DENALI_PHY_17 ro
  [31:0] PHY_GATE_TRACKING_OBS_0 — Report the on-the-fly gate measurement result for slice 0. READ-ONLY
0x4048 CTLPHY_WRAP__CTL_CFG__CTLCFG_DENALI_PHY_18
  [1:0] PHY_LP4_PST_AMBLE_0 — Controls the read postamble extension for LPDDR4 for slice 0.
{0x4000+4i} CTLPHY_WRAP__CTL_CFG__CTLCFG_DENALI_PHY_{i} (i=19..26)
  [31:0] PHY_RDLVL_PATT{i-11}_0 — Read leveling pattern {i-11} data for slice 0.
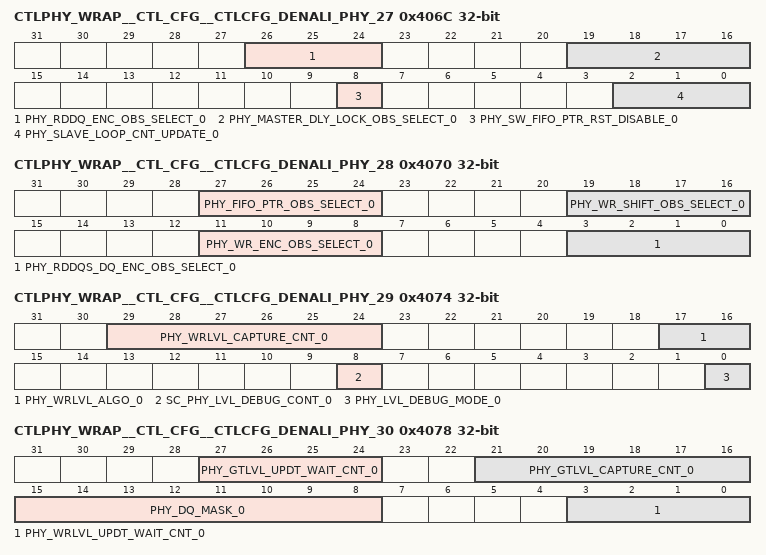
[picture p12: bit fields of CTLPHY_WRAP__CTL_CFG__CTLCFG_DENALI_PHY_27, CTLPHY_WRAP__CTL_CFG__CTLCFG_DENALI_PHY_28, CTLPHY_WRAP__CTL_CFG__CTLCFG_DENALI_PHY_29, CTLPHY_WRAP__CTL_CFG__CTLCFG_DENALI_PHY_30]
0x406C CTLPHY_WRAP__CTL_CFG__CTLCFG_DENALI_PHY_27
  [26:24] PHY_RDDQ_ENC_OBS_SELECT_0 — Select value to map the internal read DQ slave delay encoded settings to the accessible read DQ encoded slave delay observation register for slice 0.
  [19:16] PHY_MASTER_DLY_LOCK_OBS_SELECT_0 — Select value to map the internal master delay observation registers to the accessible master delay observation register for slice 0.
  [8] PHY_SW_FIFO_PTR_RST_DISABLE_0 — Disables automatic reset of the read entry FIFO pointers for slice 0. Set to 1 to disable automatic resets.
  [2:0] PHY_SLAVE_LOOP_CNT_UPDATE_0 — Reserved for future use for slice 0.
0x4070 CTLPHY_WRAP__CTL_CFG__CTLCFG_DENALI_PHY_28
  [27:24] PHY_FIFO_PTR_OBS_SELECT_0 — Select value to map the internal read entry FIFO read/write pointers to the accessible read entry FIFO pointer observation register for slice 0.
  [19:16] PHY_WR_SHIFT_OBS_SELECT_0 — Select value to map the internal write DQ/DQS automatic cycle/half_cycle shift settings to the accessible write DQ/DQS shift observation register for slice 0.
  [11:8] PHY_WR_ENC_OBS_SELECT_0 — Select value to map the internal write DQ slave delay encoded settings to the accessible write DQ encoded slave delay observation register for slice 0.
  [3:0] PHY_RDDQS_DQ_ENC_OBS_SELECT_0 — Select value to map the internal read DQS DQ rise/fall slave delay encoded settings to the accessible read DQS DQ rise/fall encoded slave delay observation registers for slice 0.
0x4074 CTLPHY_WRAP__CTL_CFG__CTLCFG_DENALI_PHY_29 access per field
  [29:24] PHY_WRLVL_CAPTURE_CNT_0 rw — Number of samples to take at each DQS slave delay setting during write leveling for slice 0.
  [17:16] PHY_WRLVL_ALGO_0 rw — Write leveling algorithm selection for slice 0.
  [8] SC_PHY_LVL_DEBUG_CONT_0 wo — Allows the leveling state machine to advance [when in debug mode] for slice 0. Set to 1 to trigger. WRITE-ONLY
  [0] PHY_LVL_DEBUG_MODE_0 rw — Enables leveling debug mode for slice 0. Set to 1 to enable.
0x4078 CTLPHY_WRAP__CTL_CFG__CTLCFG_DENALI_PHY_30
  [27:24] PHY_GTLVL_UPDT_WAIT_CNT_0 — Number of cycles + 4 to wait after changing DQS slave delay setting during gate training for slice 0. The valid range is 0x0 to 0xB.
  [21:16] PHY_GTLVL_CAPTURE_CNT_0 — Number of samples to take at each DQS slave delay setting during gate training for slice 0.
  [15:8] PHY_DQ_MASK_0 — For ECC slice, should set this register to do DQ bit mask for slice 0.
  [3:0] PHY_WRLVL_UPDT_WAIT_CNT_0 — Number of cycles to wait after changing DQS slave delay setting during write leveling for slice 0.
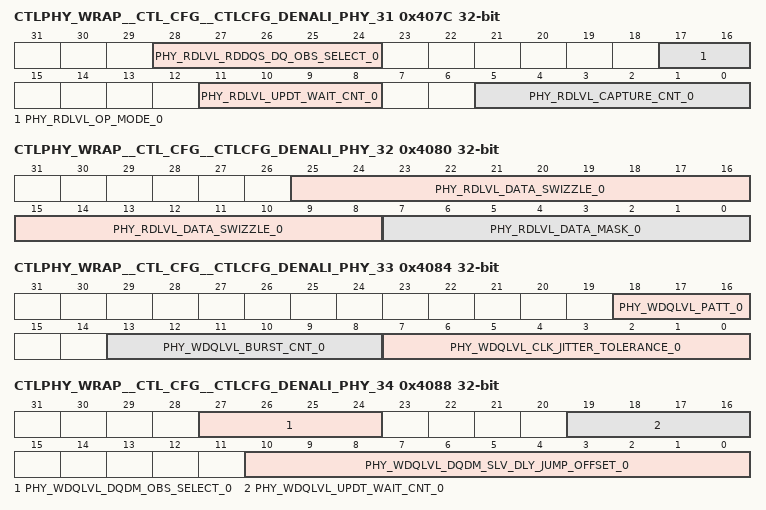
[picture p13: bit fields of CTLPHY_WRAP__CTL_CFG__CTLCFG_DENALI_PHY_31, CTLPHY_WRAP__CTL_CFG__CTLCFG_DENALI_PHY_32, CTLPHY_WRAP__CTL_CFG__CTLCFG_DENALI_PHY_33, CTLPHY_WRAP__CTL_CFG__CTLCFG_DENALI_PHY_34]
0x407C CTLPHY_WRAP__CTL_CFG__CTLCFG_DENALI_PHY_31
  [28:24] PHY_RDLVL_RDDQS_DQ_OBS_SELECT_0 — Select value to map an individual DQ data window leading/trailing edge to the leading/trailing edge observation registers during read leveling for slice 0.
  [17:16] PHY_RDLVL_OP_MODE_0 — Read leveling algorithm select for slice 0. Clear to 0 to move linearly from left to right. Set to 1 to start inside the window, move left and then move right.
  [11:8] PHY_RDLVL_UPDT_WAIT_CNT_0 — Number of cycles to wait after changing DQS slave delay setting during read leveling for slice 0.
  [5:0] PHY_RDLVL_CAPTURE_CNT_0 — Number of samples to take at each DQS slave delay setting during read leveling for slice 0.
0x4080 CTLPHY_WRAP__CTL_CFG__CTLCFG_DENALI_PHY_32
  [25:8] PHY_RDLVL_DATA_SWIZZLE_0 — Read level bit swizzling for DDR4 operation for slice 0.
  [7:0] PHY_RDLVL_DATA_MASK_0 — Per-bit mask for read leveling for slice 0. If all bits are not used, only 1 bit should be cleared to 0.
0x4084 CTLPHY_WRAP__CTL_CFG__CTLCFG_DENALI_PHY_33
  [18:16] PHY_WDQLVL_PATT_0 — Defines the training patterns to be used during the write data leveling sequence for slice 0. Bit [0] corresponds to the LFSR data training pattern. Bit [1] corresponds to the CLK data training pattern. Bit [2] corresponds to user-defined data pattern training. If multiple bits are set, the training for each of the chosen patterns will be executed and the settings that give the smallest data valid window eye will be chosen.
  [13:8] PHY_WDQLVL_BURST_CNT_0 — Defines the write/read burst length in bytes during the write data leveling sequence for slice 0.
  [7:0] PHY_WDQLVL_CLK_JITTER_TOLERANCE_0 — Defines the minimum gap requirment for the LE and TE window for slice 0.
0x4088 CTLPHY_WRAP__CTL_CFG__CTLCFG_DENALI_PHY_34
  [27:24] PHY_WDQLVL_DQDM_OBS_SELECT_0 — Select value to map an individual DQ data window leading/trailing edge to the leading/trailing edge observation registers during write data leveling for slice 0.
  [19:16] PHY_WDQLVL_UPDT_WAIT_CNT_0 — Number of cycles to wait after changing the DQ slave delay setting during write data leveling for slice 0.
  [10:0] PHY_WDQLVL_DQDM_SLV_DLY_JUMP_OFFSET_0 — Defines the slave delay jump value when the TE window is found and begin to serch TE window for slice 0.
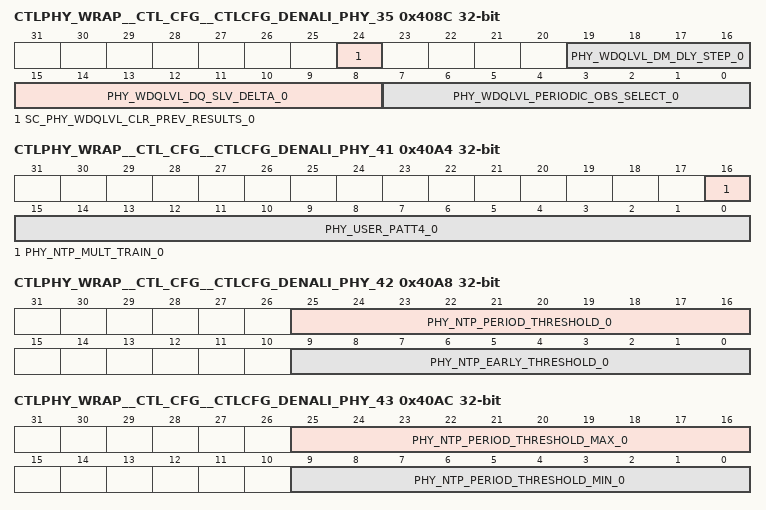
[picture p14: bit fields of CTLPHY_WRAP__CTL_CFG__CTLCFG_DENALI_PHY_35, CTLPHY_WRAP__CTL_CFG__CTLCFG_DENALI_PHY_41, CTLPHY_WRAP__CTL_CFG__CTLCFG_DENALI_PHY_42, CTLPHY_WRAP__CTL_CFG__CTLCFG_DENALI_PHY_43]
0x408C CTLPHY_WRAP__CTL_CFG__CTLCFG_DENALI_PHY_35 access per field
  [24] SC_PHY_WDQLVL_CLR_PREV_RESULTS_0 wo — Clears the previous result value to allow a clean slate comparison for future write DQ leveling results for slice 0. Set to 1 to trigger. WRITE-ONLY
  [19:16] PHY_WDQLVL_DM_DLY_STEP_0 rw — The slave delay line step for DM training for slice 0.
  [15:8] PHY_WDQLVL_DQ_SLV_DELTA_0 rw — The margin for DQ0-7's LE and TE dealy to make sure the DQ bits can work during DM training for slice 0.
  [7:0] PHY_WDQLVL_PERIODIC_OBS_SELECT_0 rw — Select value to map specific information during or post periodic write data leveling for slice 0.
0x4090 CTLPHY_WRAP__CTL_CFG__CTLCFG_DENALI_PHY_36
  [8:0] PHY_WDQLVL_DATADM_MASK_0 — Per-bit mask for write data leveling for slice 0. Set to 1 to mask any bit from the leveling process.
{0x4000+4i} CTLPHY_WRAP__CTL_CFG__CTLCFG_DENALI_PHY_{i} (i=37..40)
  [31:0] PHY_USER_PATT{i-37}_0 — User-defined pattern to be used during write data leveling for slice 0. This register holds the bytes {4i-145} to {4i-148} written/read from device.
0x40A4 CTLPHY_WRAP__CTL_CFG__CTLCFG_DENALI_PHY_41
  [16] PHY_NTP_MULT_TRAIN_0 — Control for single pass only No-Topology training for slice 0.
  [15:0] PHY_USER_PATT4_0 — User-defined pattern to be used during write data leveling for slice 0. This register holds the DM bit for the 15 to 0 DQ written/read from device.
0x40A8 CTLPHY_WRAP__CTL_CFG__CTLCFG_DENALI_PHY_42
  [25:16] PHY_NTP_PERIOD_THRESHOLD_0 — Threshold Criteria of period threshold after No-Topology training is completed for slice 0.
  [9:0] PHY_NTP_EARLY_THRESHOLD_0 — Threshold Criteria of early threshold after No-Topology training is completed for slice 0.
0x40AC CTLPHY_WRAP__CTL_CFG__CTLCFG_DENALI_PHY_43
  [25:16] PHY_NTP_PERIOD_THRESHOLD_MAX_0 — Maximum Threshold that phy_clk_wrdqs_slave_delay could cross boundary, to set period threshold/early threshold after No-Topology training is completed for slice 0.
  [9:0] PHY_NTP_PERIOD_THRESHOLD_MIN_0 — Minimum Threshold that phy_clk_wrdqs_slave_delay could cross boundary, to set period threshold/early threshold after No-Topology training is completed for slice 0.
0x40B0 CTLPHY_WRAP__CTL_CFG__CTLCFG_DENALI_PHY_44 access per field
  [23:16] PHY_FIFO_PTR_OBS_0 ro — Observation register containing read entry FIFO pointers for slice 0. READ-ONLY
  [13:8] SC_PHY_MANUAL_CLEAR_0 wo — Manual reset/clear of internal logic for slice 0. Bit [0] initiates manual setup of the read DQS gate. Bit [1] is reset of read entry FIFO pointers. Bit [2] is reset of master delay min/max lock values. Bit [3] is manual reset of master delay unlock counter. Bit [4] is reset of leveling error bit in the leveling status registers. Bit [5] is clearing of the gate tracking observation register. Set each bit to 1 to initiate/reset. WRITE-ONLY
  [0] PHY_CALVL_VREF_DRIVING_SLICE_0 rw — Indicates if slice 0 is used to drive the VREF value to the device during CA training.
0x40B4 CTLPHY_WRAP__CTL_CFG__CTLCFG_DENALI_PHY_45 ro reset 0x100000
  [31:0] PHY_LPBK_RESULT_OBS_0 — Observation register containing loopback status/results for slice 0. READ-ONLY
0x40B8 CTLPHY_WRAP__CTL_CFG__CTLCFG_DENALI_PHY_46 ro
  [26:16] PHY_MASTER_DLY_LOCK_OBS_0 — Observation register containing master delay results for slice 0. READ-ONLY
  [15:0] PHY_LPBK_ERROR_COUNT_OBS_0 — Observation register containing total number of loopback error data for slice 0. READ-ONLY
0x40BC CTLPHY_WRAP__CTL_CFG__CTLCFG_DENALI_PHY_47 ro
  [31:24] PHY_RDDQS_DQ_RISE_ADDER_SLV_DLY_ENC_OBS_0 — Observation register containing read DQS DQ rising edge adder slave delay encoded value for slice 0. READ-ONLY
  [23:16] PHY_MEAS_DLY_STEP_VALUE_0 — Observation register containing fraction of the cycle in 1 delay element, numerator with demominator of 512, for slice 0. READ-ONLY
  [14:8] PHY_RDDQS_BASE_SLV_DLY_ENC_OBS_0 — Observation register containing read DQS base slave delay encoded value for slice 0. READ-ONLY
  [6:0] PHY_RDDQ_SLV_DLY_ENC_OBS_0 — Observation register containing read DQ slave delay encoded values for slice 0. READ-ONLY
0x40C0 CTLPHY_WRAP__CTL_CFG__CTLCFG_DENALI_PHY_48 ro
  [30:24] PHY_WRDQS_BASE_SLV_DLY_ENC_OBS_0 — Observation register containing write DQS base slave delay encoded value for slice 0. READ-ONLY
  [18:8] PHY_RDDQS_GATE_SLV_DLY_ENC_OBS_0 — Observation register containing read DQS gate slave delay encoded value for slice 0. READ-ONLY
  [7:0] PHY_RDDQS_DQ_FALL_ADDER_SLV_DLY_ENC_OBS_0 — Observation register containing read DQS DQ falling edge adder slave delay encoded value for slice 0. READ-ONLY
0x40C4 CTLPHY_WRAP__CTL_CFG__CTLCFG_DENALI_PHY_49 ro
  [18:16] PHY_WR_SHIFT_OBS_0 — Observation register containing automatic half cycle and cycle shift values for slice 0. READ-ONLY
  [15:8] PHY_WR_ADDER_SLV_DLY_ENC_OBS_0 — Observation register containing write adder slave delay encoded value for slice 0. READ-ONLY
  [7:0] PHY_WRDQ_BASE_SLV_DLY_ENC_OBS_0 — Observation register containing write DQ base slave delay encoded value for slice 0. READ-ONLY
0x40C8 CTLPHY_WRAP__CTL_CFG__CTLCFG_DENALI_PHY_50 ro
  [25:16] PHY_WRLVL_HARD1_DELAY_OBS_0 — Observation register containing write leveling first hard 1 DQS slave delay for slice 0. READ-ONLY
  [9:0] PHY_WRLVL_HARD0_DELAY_OBS_0 — Observation register containing write leveling last hard 0 DQS slave delay for slice 0. READ-ONLY
0x40CC CTLPHY_WRAP__CTL_CFG__CTLCFG_DENALI_PHY_51 ro
  [20:0] PHY_WRLVL_STATUS_OBS_0 — Observation register containing write leveling status for slice 0. READ-ONLY
0x40D0 CTLPHY_WRAP__CTL_CFG__CTLCFG_DENALI_PHY_52 ro
  [25:16] PHY_GATE_SMPL2_SLV_DLY_ENC_OBS_0 — Observation register containing gate sample2 slave delay encoded values for slice 0. READ-ONLY
  [9:0] PHY_GATE_SMPL1_SLV_DLY_ENC_OBS_0 — Observation register containing gate sample1 slave delay encoded values for slice 0. READ-ONLY
0x40D4 CTLPHY_WRAP__CTL_CFG__CTLCFG_DENALI_PHY_53 ro
  [29:16] PHY_GTLVL_HARD1_DELAY_OBS_0 — Observation register containing gate training last hard 1 DQS slave delay for slice 0. READ-ONLY
  [13:0] PHY_GTLVL_HARD0_DELAY_OBS_0 — Observation register containing gate training first hard 0 DQS slave delay for slice 0. READ-ONLY
0x40D8 CTLPHY_WRAP__CTL_CFG__CTLCFG_DENALI_PHY_54 ro
  [17:0] PHY_GTLVL_STATUS_OBS_0 — Observation register containing gate training status for slice 0. READ-ONLY
0x40DC CTLPHY_WRAP__CTL_CFG__CTLCFG_DENALI_PHY_55 ro
  [25:16] PHY_RDLVL_RDDQS_DQ_TE_DLY_OBS_0 — Observation register containing read leveling data window trailing edge slave delay setting for slice 0. READ-ONLY
  [9:0] PHY_RDLVL_RDDQS_DQ_LE_DLY_OBS_0 — Observation register containing read leveling data window leading edge slave delay setting for slice 0. READ-ONLY
0x40E0 CTLPHY_WRAP__CTL_CFG__CTLCFG_DENALI_PHY_56 ro
  [1:0] PHY_RDLVL_RDDQS_DQ_NUM_WINDOWS_OBS_0 — Observation register containing read leveling number of windows found for slice 0. READ-ONLY
0x40E4 CTLPHY_WRAP__CTL_CFG__CTLCFG_DENALI_PHY_57 ro
  [31:0] PHY_RDLVL_STATUS_OBS_0 — Observation register containing read leveling status for slice 0. READ-ONLY
0x40E8 CTLPHY_WRAP__CTL_CFG__CTLCFG_DENALI_PHY_58 ro reset 0x7FF0000
  [26:16] PHY_WDQLVL_DQDM_TE_DLY_OBS_0 — Observation register containing write data leveling data window trailing edge slave delay setting for slice 0. READ-ONLY
  [10:0] PHY_WDQLVL_DQDM_LE_DLY_OBS_0 — Observation register containing write data leveling data window leading edge slave delay setting for slice 0. READ-ONLY
0x40EC CTLPHY_WRAP__CTL_CFG__CTLCFG_DENALI_PHY_59 ro
  [31:0] PHY_WDQLVL_STATUS_OBS_0 — Observation register containing write data leveling status for slice 0. READ-ONLY
0x40F0 CTLPHY_WRAP__CTL_CFG__CTLCFG_DENALI_PHY_60 ro
  [31:0] PHY_WDQLVL_PERIODIC_OBS_0 — Observation register containing periodic write data leveling status for slice 0. READ-ONLY
0x40F4 CTLPHY_WRAP__CTL_CFG__CTLCFG_DENALI_PHY_61
  [30:0] PHY_DDL_MODE_0 — DDL mode for slice 0.
0x40F8 CTLPHY_WRAP__CTL_CFG__CTLCFG_DENALI_PHY_62
  [5:0] PHY_DDL_MASK_0 — DDL mask for slice 0.
0x40FC CTLPHY_WRAP__CTL_CFG__CTLCFG_DENALI_PHY_63 ro
  [31:0] PHY_DDL_TEST_OBS_0 — DDL test observation for slice 0. READ-ONLY
0x4100 CTLPHY_WRAP__CTL_CFG__CTLCFG_DENALI_PHY_64 ro
  [31:0] PHY_DDL_TEST_MSTR_DLY_OBS_0 — DDL test observation delays for slice 0 master DDL. READ-ONLY
0x4104 CTLPHY_WRAP__CTL_CFG__CTLCFG_DENALI_PHY_65
  [24:16] PHY_RX_CAL_DQ0_0 — RX Calibration codes for DQ0 for slice 0. Bits [5:0] contain rx_cal_code_down. Bits [11:6] contain rx_cal_code_up. Bits [17:12] contain rx_cal_code2_down. Bits [23:18] contain rx_cal_code2_up.
  [8] PHY_LP4_WDQS_OE_EXTEND_0 — LPDDR4 write preamble extension enable for slice 0.
  [7:0] PHY_DDL_TRACK_UPD_THRESHOLD_0 — Specify threshold value for PHY init update tracking for slice 0.
{0x4000+4i} CTLPHY_WRAP__CTL_CFG__CTLCFG_DENALI_PHY_{i} (i=66..68)
  [24:16] PHY_RX_CAL_DQ{2i-130}_0 — RX Calibration codes for DQ{2i-130} for slice 0. Bits [5:0] contain rx_cal_code_down. Bits [11:6] contain rx_cal_code_up. Bits [17:12] contain rx_cal_code2_down. Bits [23:18] contain rx_cal_code2_up.
  [8:0] PHY_RX_CAL_DQ{2i-131}_0 — RX Calibration codes for DQ{2i-131} for slice 0. Bits [5:0] contain rx_cal_code_down. Bits [11:6] contain rx_cal_code_up. Bits [17:12] contain rx_cal_code2_down. Bits [23:18] contain rx_cal_code2_up.
0x4114 CTLPHY_WRAP__CTL_CFG__CTLCFG_DENALI_PHY_69
  [8:0] PHY_RX_CAL_DQ7_0 — RX Calibration codes for DQ7 for slice 0. Bits [5:0] contain rx_cal_code_down. Bits [11:6] contain rx_cal_code_up. Bits [17:12] contain rx_cal_code2_down. Bits [23:18] contain rx_cal_code2_up.
